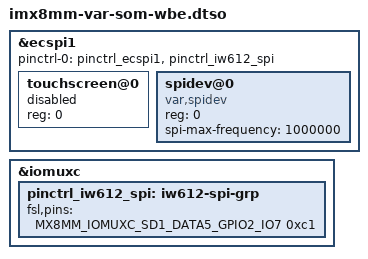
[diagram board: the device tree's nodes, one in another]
// SPDX-License-Identifier: (GPL-2.0+ OR MIT)
/*
 * Device tree overlay for VAR-SOM-MX8M-MINI 2.0 WBE (802.15.4) modules.
 *
 * Copyright 2025-2026 Variscite Ltd.
 */

/dts-v1/;
/plugin/;

#include "imx8mm-pinfunc.h"

&ecspi1 {
	#address-cells = <1>;
	#size-cells = <0>;
	pinctrl-0 = <&pinctrl_ecspi1>, <&pinctrl_iw612_spi>;

	touchscreen@0 {
		reg = <0>;
		status = "disabled";
	};

	spidev@0 {
		reg = <0>;
		compatible = "var,spidev";
		spi-max-frequency = <1000000>;
		status = "okay";
	};
};

&iomuxc {
	pinctrl_iw612_spi: iw612-spi-grp {
		fsl,pins = <
			MX8MM_IOMUXC_SD1_DATA5_GPIO2_IO7		0xc1
		>;
	};
};
